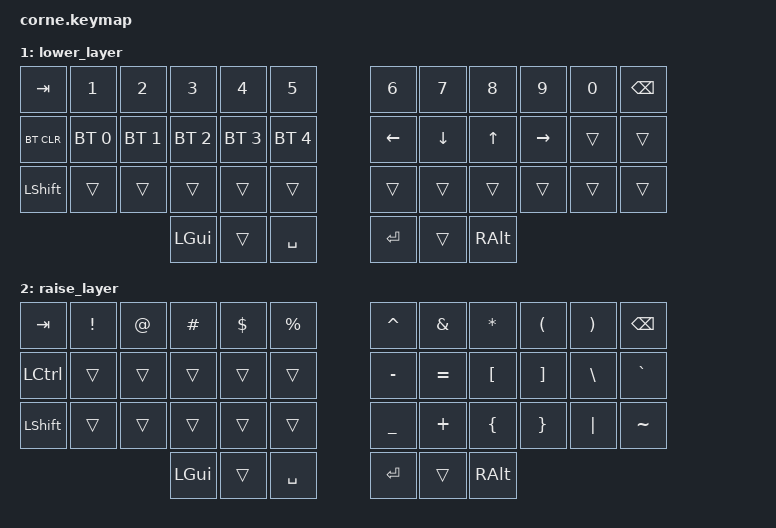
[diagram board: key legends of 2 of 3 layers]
/*
 * Copyright (c) 2020 The ZMK Contributors
 *
 * SPDX-License-Identifier: MIT
 */

#include <behaviors.dtsi>
#include <dt-bindings/zmk/keys.h>
#include <dt-bindings/zmk/bt.h>

/ {
        keymap {
                compatible = "zmk,keymap";

                default_layer {
// -----------------------------------------------------------------------------------------
// |  ESC |  Q  |  D  |  R  |  W  |  B  |   |  J  |  F   |  U  |  P  |  ;  | BKSP |
// |  TAB |  A  |  S  |  H  |  T  |  G  |   |  Y  |  N   |  E  |  O  |  I  |  '   |
// | SHFT |  Z  |  X  |  M  |  C  |  V  |   |  K  |  M   |  ,  |  .  |  /  | ESC  |
//                    | GUI | LWR | SPC |   | ENT | RSE  | ALT |
                        bindings = <
   &kp ESC   &kp Q &kp D &kp R &kp W &kp B   &kp J &kp F  &kp U     &kp P   &kp ;    &kp BSPC
   &kp TAB &kp A &kp S &kp H &kp T &kp G   &kp Y &kp N  &kp E     &kp O   &kp SEMI &kp SQT
   &kp LSHFT &kp Z &kp X &kp M &kp C &kp V   &kp K &kp L  &kp COMMA &kp DOT &kp FSLH &kp ESC
                  &kp LGUI &kp SPACE &mo 1   &kp RET &mo 2 &kp RALT
                        >;
                };
                lower_layer {
// -----------------------------------------------------------------------------------------
// |  TAB |  1  |  2  |  3  |  4  |  5  |   |  6  |  7  |  8  |  9  |  0  | BKSP |
// | BTCLR| BT1 | BT2 | BT3 | BT4 | BT5 |   | LFT | DWN |  UP | RGT |     |      |
// | SHFT |     |     |     |     |     |   |     |     |     |     |     |      |
//                    | GUI |     | SPC |   | ENT |     | ALT |
                        bindings = <
   &kp TAB    &kp N1       &kp N2       &kp N3       &kp N4       &kp N5         &kp N6   &kp N7   &kp N8 &kp N9    &kp N0 &kp BSPC
   &bt BT_CLR &bt BT_SEL 0 &bt BT_SEL 1 &bt BT_SEL 2 &bt BT_SEL 3 &bt BT_SEL 4   &kp LEFT &kp DOWN &kp UP &kp RIGHT &trans &trans
   &kp LSHFT  &trans       &trans       &trans       &trans       &trans         &trans   &trans   &trans &trans    &trans &trans
                                    &kp LGUI     &trans       &kp SPACE      &kp RET  &trans   &kp RALT
                        >;
                };

                raise_layer {
// -----------------------------------------------------------------------------------------
// |  TAB |  !  |  @  |  #  |  $  |  %  |   |  ^  |  &  |  *  |  (  |  )  | BKSP |
// | CTRL |     |     |     |     |     |   |  -  |  =  |  [  |  ]  |  \  |  `   |
// | SHFT |     |     |     |     |     |   |  _  |  +  |  {  |  }  | "|" |  ~   |
//                    | GUI |     | SPC |   | ENT |     | ALT |
                        bindings = <
   &kp  TAB  &kp EXCL &kp AT &kp HASH &kp DLLR &kp PRCNT   &kp CARET &kp AMPS  &kp ASTRK &kp LPAR &kp RPAR &kp BSPC
   &kp LCTRL &trans   &trans &trans   &trans   &trans      &kp MINUS &kp EQUAL &kp LBKT  &kp RBKT &kp BSLH &kp GRAVE
   &kp LSHFT &trans   &trans &trans   &trans   &trans      &kp UNDER &kp PLUS  &kp LBRC  &kp RBRC &kp PIPE &kp TILDE
                             &kp LGUI &trans   &kp SPACE   &kp RET   &trans    &kp RALT
                        >;
                };
        };
};
